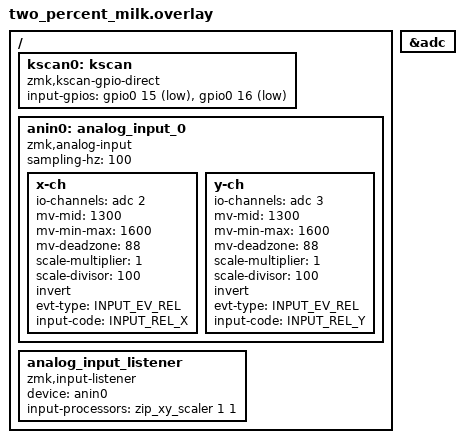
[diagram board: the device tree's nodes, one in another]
#include <dt-bindings/zmk/matrix_transform.h>
#include <zephyr/dt-bindings/input/input-event-codes.h>
#include <input/processors.dtsi>
#include <dt-bindings/zmk/input_transform.h>
#include <zephyr/dt-bindings/input/input-event-codes.h>

&adc {
	status = "okay";
};

/ {

    kscan0: kscan {
        compatible = "zmk,kscan-gpio-direct";
        input-gpios
            = <&gpio0 15 (GPIO_ACTIVE_LOW | GPIO_PULL_UP)>
            , <&gpio0 16 (GPIO_ACTIVE_LOW | GPIO_PULL_UP)>;
    };

	anin0: analog_input_0 {
		compatible = "zmk,analog-input";
		sampling-hz = <100>;
		x-ch {
			io-channels = <&adc 2>; // <--- see ain-map.png for nRF52840 5 or 10
			mv-mid = <1300>;
			mv-min-max = <1600>;
			mv-deadzone = <88>;
			scale-multiplier = <1>;
			scale-divisor = <100>;
			invert;
			evt-type = <INPUT_EV_REL>;
			input-code = <INPUT_REL_X>;
		};
		y-ch {
			io-channels = <&adc 3>; // <--- see ain-map.png for nRF52840 7 or 8
			mv-mid = <1300>;
			mv-min-max = <1600>;
			mv-deadzone = <88>;
			scale-multiplier = <1>;
			scale-divisor = <100>;
			invert;
			evt-type = <INPUT_EV_REL>;
			input-code = <INPUT_REL_Y>;

		};
	};
	
	    analog_input_listener {
        status = "okay";
        compatible = "zmk,input-listener";
        device = <&anin0>;
		input-processors = <&zip_xy_scaler 1 1>;
    };
	
};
